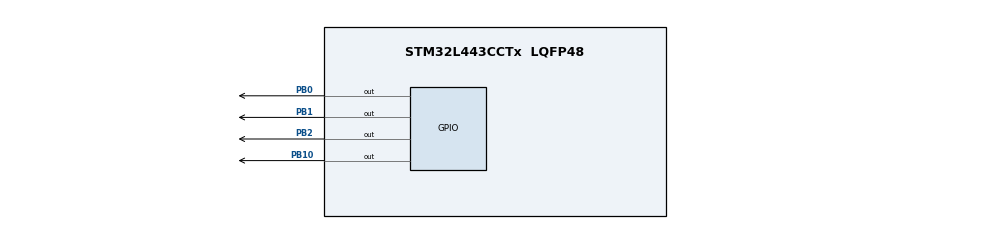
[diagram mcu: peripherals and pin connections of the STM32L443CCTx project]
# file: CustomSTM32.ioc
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Mcu.Family=STM32L4
Mcu.Name=STM32L443CCTx
Mcu.Package=LQFP48
NVIC.PriorityGroup=NVIC_PRIORITYGROUP_4
PA10.Signal=I2C1_SDA
PA9.Signal=I2C1_SCL
PB0.Signal=GPIO_Output
PB1.Signal=GPIO_Output
PB10.Signal=GPIO_Output
PB2.Signal=GPIO_Output
ProjectManager.HeapSize=0x200
ProjectManager.StackSize=0x400
ProjectManager.TargetToolchain=SW4STM32
RCC.HSE_VALUE=8000000
RCC.HSI48_VALUE=48000000
RCC.HSI_VALUE=16000000
RCC.LSE_VALUE=32768
RCC.MSI_VALUE=4000000
RCC.VCOOutputFreq_Value=32000000
board=CustomSTM32

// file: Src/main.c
//some documentation: https://developer.mbed.org/users/hes/code/mbed-src/docs/tip/group__Blocking__mode__Polling.html
//see below tutorial for additional support
//http://lightsurge2.blogspot.com/2014/06/i2c-nucleo-stm32f401re-and-freertos.html
/**
  ******************************************************************************
  * File Name          : main.c
  * Description        : Main program body
  ******************************************************************************
  *
  * COPYRIGHT(c) 2016 STMicroelectronics
  *
  * Redistribution and use in source and binary forms, with or without modification,
  * are permitted provided that the following conditions are met:
  *   1. Redistributions of source code must retain the above copyright notice,
  *      this list of conditions and the following disclaimer.
  *   2. Redistributions in binary form must reproduce the above copyright notice,
  *      this list of conditions and the following disclaimer in the documentation
  *      and/or other materials provided with the distribution.
  *   3. Neither the name of STMicroelectronics nor the names of its contributors
  *      may be used to endorse or promote products derived from this software
  *      without specific prior written permission.
  *
  * THIS SOFTWARE IS PROVIDED BY THE COPYRIGHT HOLDERS AND CONTRIBUTORS "AS IS"
  * AND ANY EXPRESS OR IMPLIED WARRANTIES, INCLUDING, BUT NOT LIMITED TO, THE
  * IMPLIED WARRANTIES OF MERCHANTABILITY AND FITNESS FOR A PARTICULAR PURPOSE ARE
  * DISCLAIMED. IN NO EVENT SHALL THE COPYRIGHT HOLDER OR CONTRIBUTORS BE LIABLE
  * FOR ANY DIRECT, INDIRECT, INCIDENTAL, SPECIAL, EXEMPLARY, OR CONSEQUENTIAL
  * DAMAGES (INCLUDING, BUT NOT LIMITED TO, PROCUREMENT OF SUBSTITUTE GOODS OR
  * SERVICES; LOSS OF USE, DATA, OR PROFITS; OR BUSINESS INTERRUPTION) HOWEVER
  * CAUSED AND ON ANY THEORY OF LIABILITY, WHETHER IN CONTRACT, STRICT LIABILITY,
  * OR TORT (INCLUDING NEGLIGENCE OR OTHERWISE) ARISING IN ANY WAY OUT OF THE USE
  * OF THIS SOFTWARE, EVEN IF ADVISED OF THE POSSIBILITY OF SUCH DAMAGE.
  *
  ******************************************************************************
  */
#include "stm32l4xx_hal.h"

/* USER CODE BEGIN PV */
/* Private variables ---------------------------------------------------------*/

/* USER CODE END PV */

void SystemClock_Config(void);
void Error_Handler(void);
static void MX_GPIO_Init(void);

/* USER CODE BEGIN PFP */
/* Private function prototypes -----------------------------------------------*/

/* USER CODE END PFP */

/* USER CODE BEGIN 0 */

#define I2C_ADDRESS (0x21 <<1)

/* USER CODE END 0 */

int main(void)
{

  /* MCU Configuration----------------------------------------------------------*/

  /* Reset of all peripherals, Initializes the Flash interface and the Systick. */
  HAL_Init();

  /* Configure the system clock */
  SystemClock_Config();

  /* Initialize all configured peripherals */
  MX_GPIO_Init();

  /* USER CODE BEGIN 2 */
  I2C_HandleTypeDef I2cHandle;

   uint8_t count = 0;
   char data[2];

   /* We need to send data to the direction
    * register first to setup our led counter as output
    */
   data[0] = 0x00;
   data[1] = 0x00;
   HAL_I2C_Master_Transmit(&I2cHandle, (uint16_t) (I2C_ADDRESS), (uint8_t *) data, 2, 1000);

   /* Infinite loop */
   data[0] = 0x14;
   for(;;)
   {
     data[1] = count;
     HAL_I2C_Master_Transmit(&I2cHandle, (uint16_t) (I2C_ADDRESS), (uint8_t*) data, 2, 1000);
     count++;
     HAL_Delay(100);
   }

  /* USER CODE END 2 */

  /* Infinite loop */
  while (1)
  {

  }

}

/** System Clock Configuration
*/
void SystemClock_Config(void)
{

  RCC_OscInitTypeDef RCC_OscInitStruct;
  RCC_ClkInitTypeDef RCC_ClkInitStruct;

  RCC_OscInitStruct.OscillatorType = RCC_OSCILLATORTYPE_MSI;
  RCC_OscInitStruct.MSIState = RCC_MSI_ON;
  RCC_OscInitStruct.MSICalibrationValue = 0;
  RCC_OscInitStruct.MSIClockRange = RCC_MSIRANGE_6;
  RCC_OscInitStruct.PLL.PLLState = RCC_PLL_NONE;
  if (HAL_RCC_OscConfig(&RCC_OscInitStruct) != HAL_OK)
  {
    Error_Handler();
  }

  RCC_ClkInitStruct.ClockType = RCC_CLOCKTYPE_HCLK|RCC_CLOCKTYPE_SYSCLK
                              |RCC_CLOCKTYPE_PCLK1|RCC_CLOCKTYPE_PCLK2;
  RCC_ClkInitStruct.SYSCLKSource = RCC_SYSCLKSOURCE_MSI;
  RCC_ClkInitStruct.AHBCLKDivider = RCC_SYSCLK_DIV1;
  RCC_ClkInitStruct.APB1CLKDivider = RCC_HCLK_DIV1;
  RCC_ClkInitStruct.APB2CLKDivider = RCC_HCLK_DIV1;
  if (HAL_RCC_ClockConfig(&RCC_ClkInitStruct, FLASH_LATENCY_0) != HAL_OK)
  {
    Error_Handler();
  }

  __HAL_RCC_PWR_CLK_ENABLE();

  if (HAL_PWREx_ControlVoltageScaling(PWR_REGULATOR_VOLTAGE_SCALE1) != HAL_OK)
  {
    Error_Handler();
  }

  HAL_SYSTICK_Config(HAL_RCC_GetHCLKFreq()/1000);

  HAL_SYSTICK_CLKSourceConfig(SYSTICK_CLKSOURCE_HCLK);

  /* SysTick_IRQn interrupt configuration */
  HAL_NVIC_SetPriority(SysTick_IRQn, 0, 0);
}

/** Configure pins as
        * Analog
        * Input
        * Output
        * EVENT_OUT
        * EXTI
     PA9   ------> I2C1_SCL
     PA10   ------> I2C1_SDA
*/
static void MX_GPIO_Init(void)
{

  GPIO_InitTypeDef GPIO_InitStruct;

  /* GPIO Ports Clock Enable */
  __HAL_RCC_GPIOB_CLK_ENABLE();
  __HAL_RCC_GPIOA_CLK_ENABLE();

  /*Configure GPIO pin Output Level */
  HAL_GPIO_WritePin(GPIOB, GPIO_PIN_0|GPIO_PIN_1|GPIO_PIN_2|GPIO_PIN_10, GPIO_PIN_RESET);

  /*Configure GPIO pins : PB0 PB1 PB2 PB10 */
  GPIO_InitStruct.Pin = GPIO_PIN_0|GPIO_PIN_1|GPIO_PIN_2|GPIO_PIN_10;
  GPIO_InitStruct.Mode = GPIO_MODE_OUTPUT_PP;
  GPIO_InitStruct.Pull = GPIO_NOPULL;
  GPIO_InitStruct.Speed = GPIO_SPEED_FREQ_LOW;
  HAL_GPIO_Init(GPIOB, &GPIO_InitStruct);

  /*Configure GPIO pins : PA9 PA10 */
  GPIO_InitStruct.Pin = GPIO_PIN_9|GPIO_PIN_10;
  GPIO_InitStruct.Mode = GPIO_MODE_AF_OD;
  GPIO_InitStruct.Pull = GPIO_PULLUP;
  GPIO_InitStruct.Speed = GPIO_SPEED_FREQ_VERY_HIGH;
  GPIO_InitStruct.Alternate = GPIO_AF4_I2C1;
  HAL_GPIO_Init(GPIOA, &GPIO_InitStruct);

}

void Error_Handler(void)
{
  while(1)
  {
  }
}

/************************ (C) COPYRIGHT STMicroelectronics *****END OF FILE****/
